# LPC55S6x register map
Vendor: nxp.com; File version: 1.0
CPU: CM33 r2p0, little endian, MPU, FPU, VTOR, 3 interrupt priority bits
Registers are 32-bit, read-write, reset 0x0 unless marked. A register's access mark holds for its fields unless they carry their own. Offsets are from the block's base; [hi:lo] are bit positions; lines under a group give offsets from that group; {n}, {i} and the like mark numbered series.

## RNG
Base 0x4003A000
0x00 RANDOM_NUMBER ro — This register contains a random 32 bit number which is computed on demand, at each time it is read
  [31:0] RANDOM_NUMBER — This register contains a random 32 bit number which is computed on demand, at each time it is read.
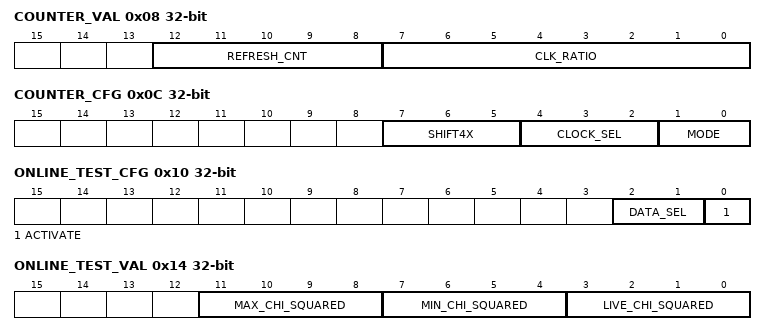
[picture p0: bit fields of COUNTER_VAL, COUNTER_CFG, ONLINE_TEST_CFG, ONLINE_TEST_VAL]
0x08 COUNTER_VAL
  [12:8] REFRESH_CNT ro — Incremented (till max possible value) each time COUNTER was updated since last reading to any *_NUMBER.
  [7:0] CLK_RATIO ro — Gives the ratio between the internal clocks frequencies and the register clock frequency for evaluation and certification purposes.
0x0C COUNTER_CFG
  [7:5] SHIFT4X — To be used to add precision to clock_ratio and determine 'entropy refill'.
  [4:2] CLOCK_SEL — Selects the internal clock on which to compute statistics.
  [1:0] MODE — 00: disabled 01: update once.
0x10 ONLINE_TEST_CFG
  [2:1] DATA_SEL — Selects source on which to apply online test: 00: LSB of COUNTER: raw data from one or all sources of entropy 01: MSB of COUNTER: raw data from one or all sources of entropy 10: RANDOM_NUMBER 11: ENCRYPTED_NUMBER 'activate' should be set to 'disabled' before changing this field.
  [0] ACTIVATE — 0: disabled 1: activated Update rythm for VAL depends on COUNTER_CFG if data_sel is set to COUNTER.
0x14 ONLINE_TEST_VAL
  [11:8] MAX_CHI_SQUARED ro — This field is reset when 'activate'==0.
  [7:4] MIN_CHI_SQUARED ro — This field is reset when 'activate'==0.
  [3:0] LIVE_CHI_SQUARED ro — This value is updated as described in field 'activate'.
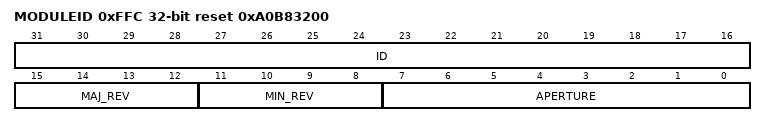
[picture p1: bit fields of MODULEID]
0xFFC MODULEID ro reset 0xA0B83200 — IP identifier
  [31:16] ID — Identifier.
  [15:12] MAJ_REV — Major revision i.
  [11:8] MIN_REV — Minor revision i.
  [7:0] APERTURE — Aperture i.

## PLU — LPC80X Programmable Logic Unit (PLU)
Base 0x4003D000
{0x0+0x20*i} LUT[{i}] (i=0..25) group
  {0x0+4j} LUT_INP_MUX{j} (j=0..4) — LUTn input x MUX
    [5:0] LUTn_INPx — Selects the input source to be connected to LUT0 input0. For each LUT, the slot associated with the output from LUTn itself is tied low.
      {v}=plu_inputs{v} (The PLU primary inputs {v}.) (v=0..5); {v}=lut_outputs{v-6} (The output of LUT{v-6}.) (v=6..31); {v}=state{v-32} (v=32..35)
{0x800+4i} LUT_TRUTH[{i}] (i=0..25) — Specifies the Truth Table contents for LUT0
  [31:0] LUTn_TRUTH — Specifies the Truth Table contents for LUT0..
0x900 OUTPUTS — Provides the current state of the 8 designated PLU Outputs.
  [7:0] OUTPUT_STATE ro — Provides the current state of the 8 designated PLU Outputs..
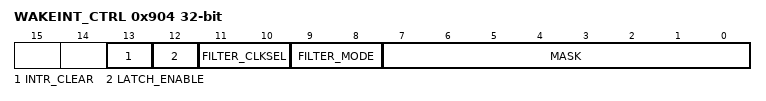
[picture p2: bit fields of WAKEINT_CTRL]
0x904 WAKEINT_CTRL — Wakeup interrupt control for PLU
  [13] INTR_CLEAR write-1-clears — Write to clear wakeint_latched
  [12] LATCH_ENABLE — latch the interrupt , then can be cleared with next bit INTR_CLEAR
  [11:10] FILTER_CLKSEL — hclk is divided by 2**filter_clksel.
    0=FRO1MHZ (Selects the 1 MHz low-power oscillator as the filter clock.); 1=FRO12MHZ (Selects the 12 Mhz FRO as the filter clock.); 2=OTHER_CLOCK (Selects a third filter clock source, if provided.)
  [9:8] FILTER_MODE — control input of the PLU, add filtering for glitch.
    0=BYPASS (Bypass mode.); 1=FILTER1CLK (Filter 1 clock period.); 2=FILTER2CLK (Filter 2 clock period.); 3=FILTER3CLK (Filter 3 clock period.)
  [7:0] MASK — Interrupt mask (which of the 8 PLU Outputs contribute to interrupt)
{0xC00+4i} OUTPUT_MUX[{i}] (i=0..7) — Selects the source to be connected to PLU Output 0
  [4:0] OUTPUTn — Selects the source to be connected to PLU Output 0.
    {v}=plu_output{v} (The PLU output {v}.) (v=0..25); {v}=state{v-26} (v=26..29)

## FLEXCOMM0 — Flexcomm serial communication
Base 0x40086000
Same registers: FLEXCOMM1 0x40087000, FLEXCOMM2 0x40088000, FLEXCOMM3 0x40089000, FLEXCOMM4 0x4008A000, FLEXCOMM5 0x40096000, FLEXCOMM6 0x40097000, FLEXCOMM7 0x40098000, FLEXCOMM8 0x4009F000
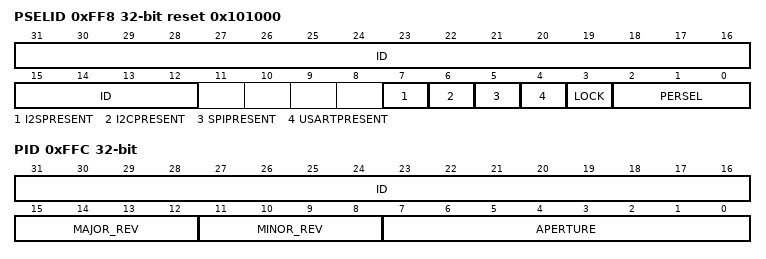
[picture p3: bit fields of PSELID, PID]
0xFF8 PSELID reset 0x101000 — Peripheral Select and Flexcomm ID register.
  [31:12] ID ro — Flexcomm ID.
  [7] I2SPRESENT ro — I 2S present indicator. This field is Read-only.
    0=NOT_PRESENT (This Flexcomm does not include the I2S function.); 1=PRESENT (This Flexcomm includes the I2S function.)
  [6] I2CPRESENT ro — I2C present indicator. This field is Read-only.
    0=NOT_PRESENT (This Flexcomm does not include the I2C function.); 1=PRESENT (This Flexcomm includes the I2C function.)
  [5] SPIPRESENT ro — SPI present indicator. This field is Read-only.
    0=NOT_PRESENT (This Flexcomm does not include the SPI function.); 1=PRESENT (This Flexcomm includes the SPI function.)
  [4] USARTPRESENT ro — USART present indicator. This field is Read-only.
    0=NOT_PRESENT (This Flexcomm does not include the USART function.); 1=PRESENT (This Flexcomm includes the USART function.)
  [3] LOCK — Lock the peripheral select. This field is writable by software.
    0=UNLOCKED (Peripheral select can be changed by software.); 1=LOCKED (Peripheral select is locked and cannot be changed until this Flexcomm or the entire device is reset.)
  [2:0] PERSEL — Peripheral Select. This field is writable by software.
    0=NO_PERIPH_SELECTED (No peripheral selected.); 1=USART (USART function selected.); 2=SPI (SPI function selected.); 3=I2C (I2C function selected.); 4=I2S_TRANSMIT (I2S transmit function selected.); 5=I2S_RECEIVE (I2S receive function selected.)
0xFFC PID ro — Peripheral identification register.
  [31:16] ID — Module identifier for the selected function.
  [15:12] MAJOR_REV — Major revision of module implementation.
  [11:8] MINOR_REV — Minor revision of module implementation.
  [7:0] APERTURE — size aperture for the register port on the bus (APB or AHB).

## MAILBOX
Base 0x4008B000
{0x0+0x10*i} MBOXIRQ[{i}] (i=0..1) group
  0x00 IRQ — Interrupt request register for the Cortex-M0+ CPU.
    [31:0] INTREQ — If any bit is set, an interrupt request is sent to the Cortex-M0+ interrupt controller.
  0x04 IRQSET wo reset not defined — Set bits in IRQ0
    [31:0] INTREQSET — Writing 1 sets the corresponding bit in the IRQ0 register.
  0x08 IRQCLR wo reset not defined — Clear bits in IRQ0
    [31:0] INTREQCLR — Writing 1 clears the corresponding bit in the IRQ0 register.
0xF8 MUTEX reset 0x1 — Mutual exclusion register[1]
  [0] EX — Cleared when read, set when written. See usage description above.

## CRC_ENGINE
Base 0x40095000
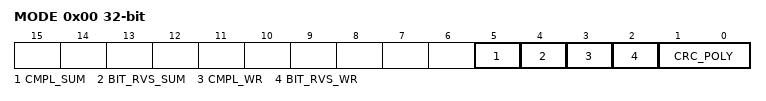
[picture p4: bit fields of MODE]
0x00 MODE — CRC mode register
  [5] CMPL_SUM — CRC sum complement: 1 = 1's complement for CRC_SUM 0 = No 1's complement for CRC_SUM
  [4] BIT_RVS_SUM — CRC sum bit order: 1 = Bit order reverse for CRC_SUM 0 = No bit order reverse for CRC_SUM
  [3] CMPL_WR — Data complement: 1 = 1's complement for CRC_WR_DATA 0 = No 1's complement for CRC_WR_DATA
  [2] BIT_RVS_WR — Data bit order: 1 = Bit order reverse for CRC_WR_DATA (per byte) 0 = No bit order reverse for CRC_WR_DATA (per byte)
  [1:0] CRC_POLY — CRC polynomial: 1X = CRC-32 polynomial 01 = CRC-16 polynomial 00 = CRC-CCITT polynomial
0x04 SEED reset 0xFFFF — CRC seed register
  [31:0] CRC_SEED — A write access to this register will load CRC seed value to CRC_SUM register with selected bit order and 1's complement pre-processes. A write access to this register will overrule the CRC calculation in progresses.
0x08 SUM ro reset 0xFFFF (SUM_WR_DATA view) — CRC checksum register
  [31:0] CRC_SUM — The most recent CRC sum can be read through this register with selected bit order and 1's complement post-processes.
0x08 WR_DATA wo reset not defined (SUM_WR_DATA view) — CRC data register
  [31:0] CRC_WR_DATA — Data written to this register will be taken to perform CRC calculation with selected bit order and 1's complement pre-process. Any write size 8, 16 or 32-bit are allowed and accept back-to-back transactions.

## DBGMAILBOX — MCU Debugger Mailbox
Base 0x4009C000
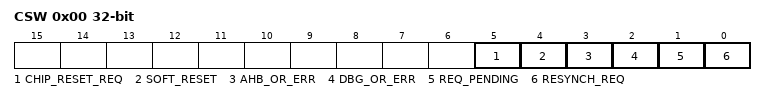
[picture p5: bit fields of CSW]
0x00 CSW — CRC mode register
  [5] CHIP_RESET_REQ wo — Write only bit. Once written will cause the chip to reset (note that the DM is not reset by this reset as it is only resettable by a SOFT reset or a POR/BOD event)
  [4] SOFT_RESET — Soft Reset for DM (write-only from AHB, not readable and selfclearing). A write to this bit will cause a soft reset for DM.
  [3] AHB_OR_ERR — AHB overrun Error (Return value overwritten by ROM)
  [2] DBG_OR_ERR — Debugger overrun error (previous REQUEST overwritten before being picked up by ROM)
  [1] REQ_PENDING — Request is pending from debugger (i.e unread value in REQUEST)
  [0] RESYNCH_REQ — Debugger will set this bit to 1 to request a resynchronrisation
0x04 REQUEST reset 0xFFFF — CRC seed register
  [31:0] REQ — Request Value
0x08 RETURN — Return value from ROM.
  [31:0] RET — The Return value from ROM.
0xFC ID ro reset 0x2A0000 — Identification register
  [31:0] ID — Identification value.

## Notices in the file
Copyright 2016-2019 NXP
All rights reserved.
SPDX-License-Identifier: BSD-3-Clause
